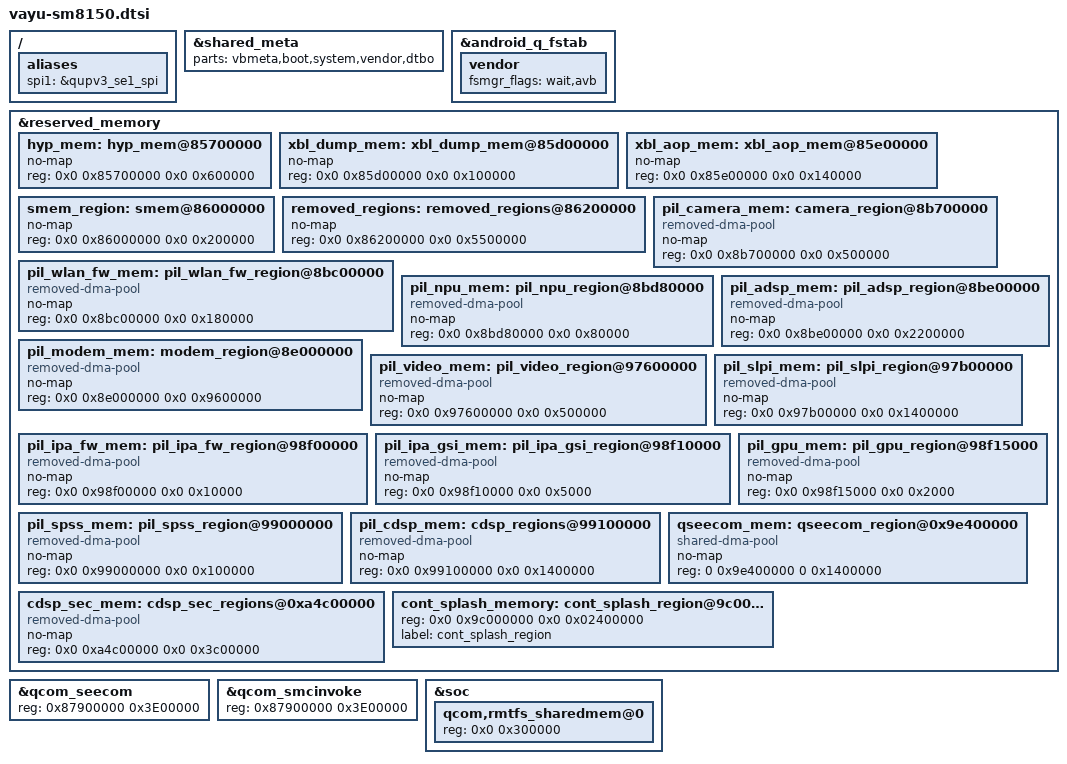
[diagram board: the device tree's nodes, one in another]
/* Copyright (c) 2021, The Linux Foundation. All rights reserved.
*  Copyright (c) 2021, Jebaitedneko <Jebaitedneko@gmail.com>.
*
* This program is free software; you can redistribute it and/or modify
* it under the terms of the GNU General Public License version 2 and
* only version 2 as published by the Free Software Foundation.
*
* This program is distributed in the hope that it will be useful,
* but WITHOUT ANY WARRANTY; without even the implied warranty of
* MERCHANTABILITY or FITNESS FOR A PARTICULAR PURPOSE.  See the
* GNU General Public License for more details.
*/

/* sm8150 */

/ {

	aliases {

		spi1 = &qupv3_se1_spi;
	};
};

&shared_meta {

	parts = "vbmeta,boot,system,vendor,dtbo";
};

&android_q_fstab {

	/delete-node/ odm;

	vendor {

		fsmgr_flags = "wait,avb";
	};
};

&reserved_memory {

	/delete-node/ hyp_mem;
	/delete-node/ xbl_aop_mem;
	/delete-node/ smem;
	/delete-node/ removed_regions;
	/delete-node/ camera_region;
	/delete-node/ pil_wlan_fw_region;
	/delete-node/ pil_npu_region;
	/delete-node/ pil_adsp_region;
	/delete-node/ modem_region;
	/delete-node/ pil_video_region;
	/delete-node/ pil_slpi_region;
	/delete-node/ pil_ipa_fw_region;
	/delete-node/ pil_ipa_gsi_region;
	/delete-node/ pil_gpu_region;
	/delete-node/ pil_spss_region;
	/delete-node/ cdsp_regions;
	/delete-node/ qseecom_region;
	/delete-node/ cdsp_sec_regions;
	/delete-node/ cont_splash_region;
	/delete-node/ disp_rdump_region;

	hyp_mem: hyp_mem@85700000 {
	
		no-map;
		reg = <0x0 0x85700000 0x0 0x600000>;
	};

	xbl_dump_mem: xbl_dump_mem@85d00000 {
	
		no-map;
		reg = <0x0 0x85d00000 0x0 0x100000>;
	};

	xbl_aop_mem: xbl_aop_mem@85e00000 {

		no-map;
		reg = <0x0 0x85e00000 0x0 0x140000>;
	};

	smem_region: smem@86000000 {

		no-map;
		reg = <0x0 0x86000000 0x0 0x200000>;
	};

	removed_regions: removed_regions@86200000 {

		no-map;
		reg = <0x0 0x86200000 0x0 0x5500000>;
	};

	pil_camera_mem: camera_region@8b700000 {

		compatible = "removed-dma-pool";
		no-map;
		reg = <0x0 0x8b700000 0x0 0x500000>;
	};

	pil_wlan_fw_mem: pil_wlan_fw_region@8bc00000 {

		compatible = "removed-dma-pool";
		no-map;
		reg = <0x0 0x8bc00000 0x0 0x180000>;
	};

	pil_npu_mem: pil_npu_region@8bd80000 {

		compatible = "removed-dma-pool";
		no-map;
		reg = <0x0 0x8bd80000 0x0 0x80000>;
	};

	pil_adsp_mem: pil_adsp_region@8be00000 {

		compatible = "removed-dma-pool";
		no-map;
		reg = <0x0 0x8be00000 0x0 0x2200000>;
	};

	pil_modem_mem: modem_region@8e000000 {

		compatible = "removed-dma-pool";
		no-map;
		reg = <0x0 0x8e000000 0x0 0x9600000>;
	};

	pil_video_mem: pil_video_region@97600000 {

		compatible = "removed-dma-pool";
		no-map;
		reg = <0x0 0x97600000 0x0 0x500000>;
	};

	pil_slpi_mem: pil_slpi_region@97b00000 {

		compatible = "removed-dma-pool";
		no-map;
		reg = <0x0 0x97b00000 0x0 0x1400000>;
	};

	pil_ipa_fw_mem: pil_ipa_fw_region@98f00000 {

		compatible = "removed-dma-pool";
		no-map;
		reg = <0x0 0x98f00000 0x0 0x10000>;
	};

	pil_ipa_gsi_mem: pil_ipa_gsi_region@98f10000 {

		compatible = "removed-dma-pool";
		no-map;
		reg = <0x0 0x98f10000 0x0 0x5000>;
	};

	pil_gpu_mem: pil_gpu_region@98f15000 {

		compatible = "removed-dma-pool";
		no-map;
		reg = <0x0 0x98f15000 0x0 0x2000>;
	};

	pil_spss_mem: pil_spss_region@99000000 {

		compatible = "removed-dma-pool";
		no-map;
		reg = <0x0 0x99000000 0x0 0x100000>;
	};

	pil_cdsp_mem: cdsp_regions@99100000 {

		compatible = "removed-dma-pool";
		no-map;
		reg = <0x0 0x99100000 0x0 0x1400000>;
	};

	qseecom_mem: qseecom_region@0x9e400000 {

		compatible = "shared-dma-pool";
		no-map;
		reg = <0 0x9e400000 0 0x1400000>;
	};

	cdsp_sec_mem: cdsp_sec_regions@0xa4c00000 {

		compatible = "removed-dma-pool";
		no-map;
		reg = <0x0 0xa4c00000 0x0 0x3c00000>;
	};

	cont_splash_memory: cont_splash_region@9c000000 {

		reg = <0x0 0x9c000000 0x0 0x02400000>;
		label = "cont_splash_region";
	};
};

&qcom_seecom {

	reg = <0x87900000 0x3E00000>;
};

&qcom_smcinvoke {

	reg = <0x87900000 0x3E00000>;
};

&soc {

	qcom,rmtfs_sharedmem@0 {

		reg = <0x0 0x300000>;
	};
};
